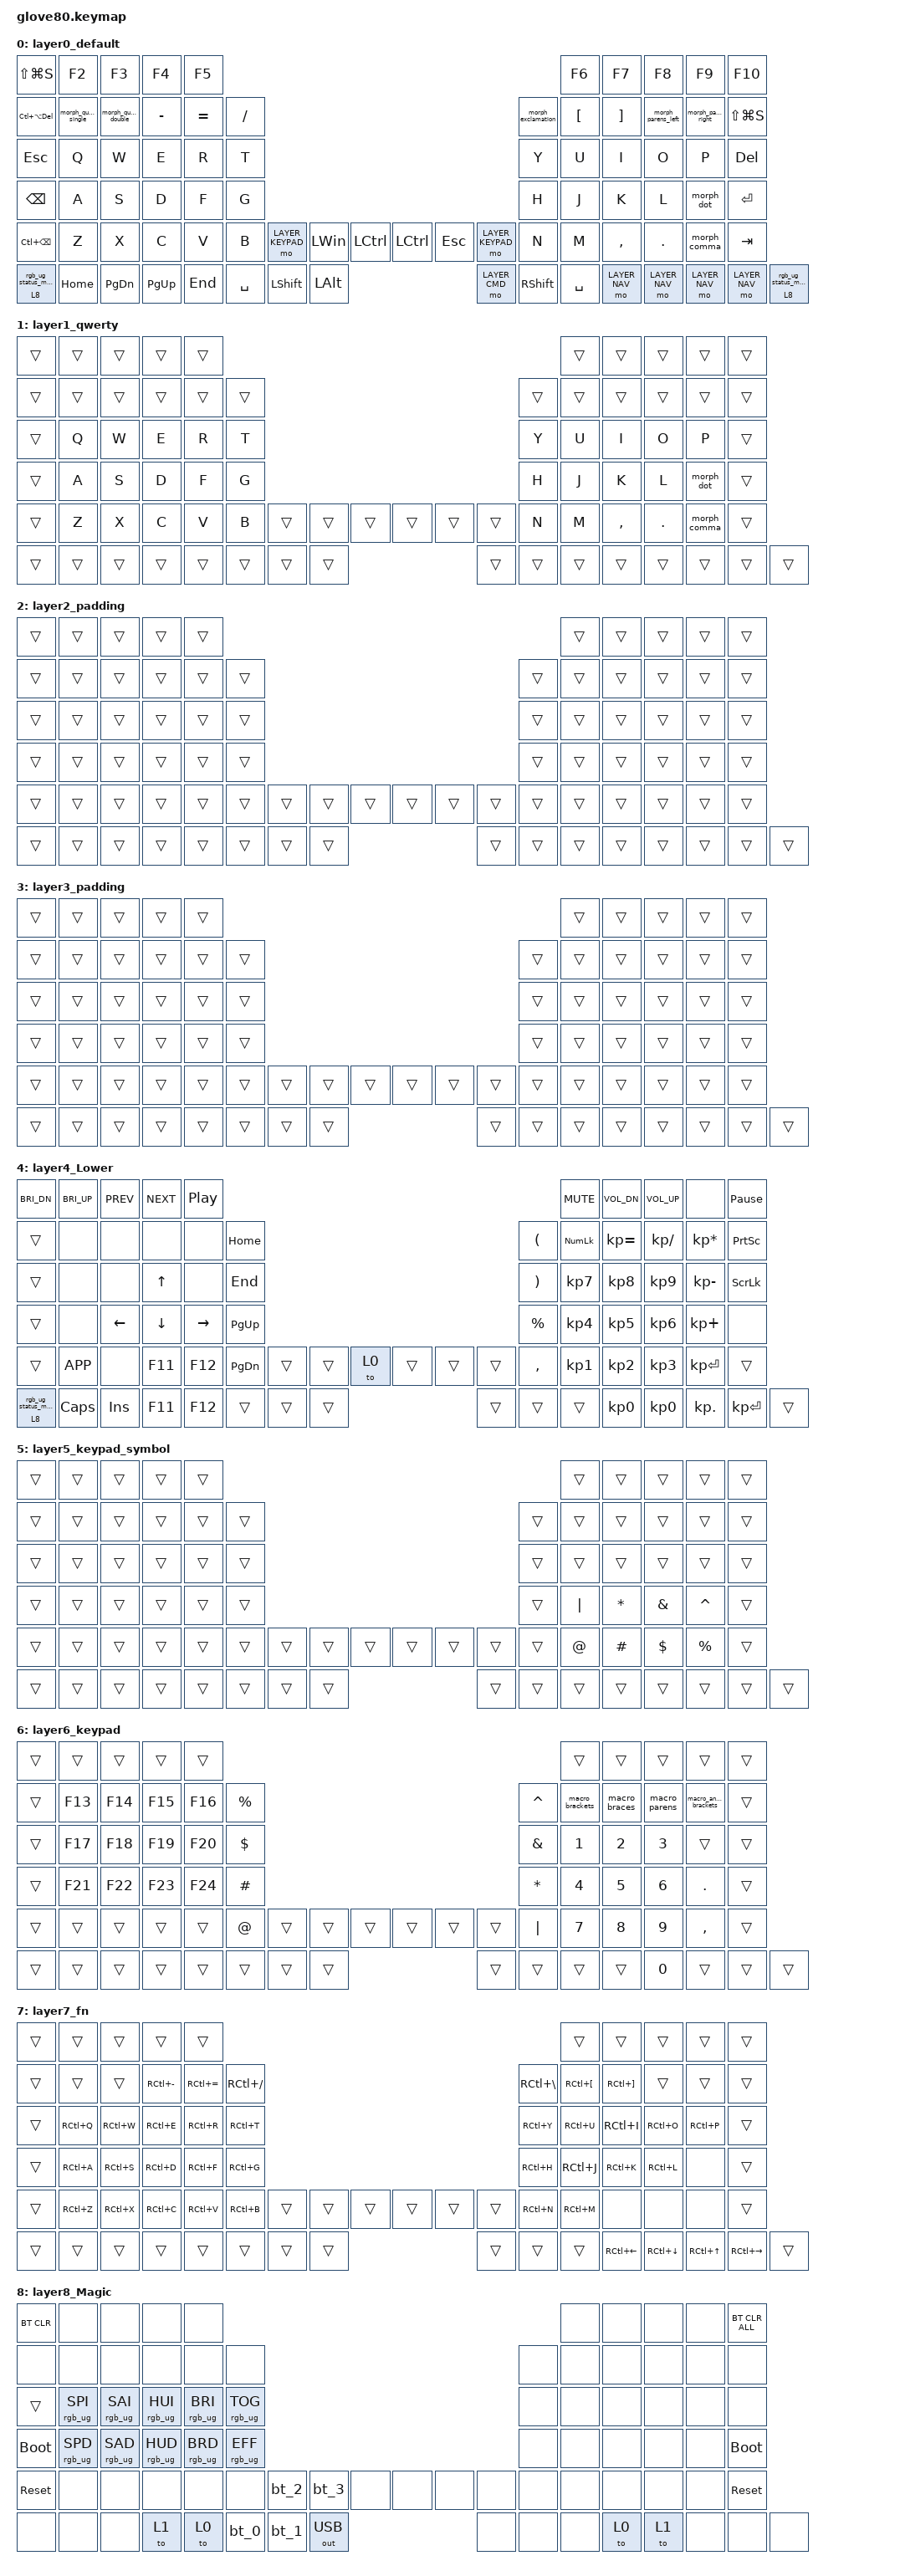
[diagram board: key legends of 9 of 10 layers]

/*
 * Copyright (c) 2020 The ZMK Contributors
 * Copyright (c) 2022 Innaworks Development Limited, trading as MoErgo
 *
 * SPDX-License-Identifier: MIT
 */


/* THIS FILE WAS GENERATED BY GLOVE80 LAYOUT EDITOR
 *
 * This file was generated automatically. You may or may not want to
 * edit it directly.
 */

#include <behaviors.dtsi>
/* Include all behaviour includes needed by system behaviors/macros */
#include <dt-bindings/zmk/outputs.h>

/* Include behaviour includes needed by key binds - automatically generated */
#include <dt-bindings/zmk/keys.h>
#include <dt-bindings/zmk/bt.h>
#include <dt-bindings/zmk/rgb.h>
#include <dt-bindings/zmk/outputs.h>

#define LAYER_KEYPAD 6
#define LAYER_CMD 7
#define LAYER_NAV 9

/ {
    /* Glove80 system behavior & macros */
    behaviors {
        // For the "layer" key, it'd nice to be able to use it as either a shift or a toggle.
        // Configure it as a tap dance, so the first tap (or hold) is a &mo and the second tap is a &to
        lower: tap_dance_0 {
            compatible = "zmk,behavior-tap-dance";
            label = "LAYER_TAP_DANCE";
            #binding-cells = <0>;
            tapping-term-ms = <200>;
            bindings = <&mo 1>, <&to 1>;
        };
    };

    combos {
        compatible = "zmk,combos";
        combo_esc {
            timeout-ms = <50>;
            key-positions = <52 57>; // This needs to change for each board
            bindings = <&kp BSPC>;
        };
    };

    macros {
        rgb_ug_status_macro: rgb_ug_status_macro_0 {
            label = "RGB_UG_STATUS";
            compatible = "zmk,behavior-macro";
            #binding-cells = <0>;
            bindings = <&rgb_ug RGB_STATUS>;
        };

        bt_0: bt_profile_macro_0 {
            label = "BT_0";
            compatible = "zmk,behavior-macro";
            #binding-cells = <0>;
            bindings = <&out OUT_BLE>, <&bt BT_SEL 0>;
        };

        bt_1: bt_profile_macro_1 {
            label = "BT_1";
            compatible = "zmk,behavior-macro";
            #binding-cells = <0>;
            bindings = <&out OUT_BLE>, <&bt BT_SEL 1>;
        };

        bt_2: bt_profile_macro_2 {
            label = "BT_2";
            compatible = "zmk,behavior-macro";
            #binding-cells = <0>;
            bindings = <&out OUT_BLE>, <&bt BT_SEL 2>;
        };

        bt_3: bt_profile_macro_3 {
            label = "BT_3";
            compatible = "zmk,behavior-macro";
            #binding-cells = <0>;
            bindings = <&out OUT_BLE>, <&bt BT_SEL 3>;
        };

        macro_quotes: macro_quotes {
            compatible = "zmk,behavior-macro";
            label = "macro_quotes";
            #binding-cells = <0>;
            bindings = <&kp SQT>, <&kp SQT>, <&kp LEFT>;
        };

        macro_dquotes: macro_dquotes {
            compatible = "zmk,behavior-macro";
            label = "macro_dquotes";
            #binding-cells = <0>;
            bindings = <&kp DQT>, <&kp DQT>, <&kp LEFT>;
        };

        macro_braces: macro_braces {
            compatible = "zmk,behavior-macro";
            label = "macro_braces";
            #binding-cells = <0>;
            bindings = <&kp LBRC>, <&kp RBRC>, <&kp LEFT>;
        };

        macro_parens: macro_parens {
            compatible = "zmk,behavior-macro";
            label = "macro_parens";
            #binding-cells = <0>;
            bindings = <&kp LPAR>, <&kp RPAR>, <&kp LEFT>;
        };

        macro_brackets: macro_brackets {
            compatible = "zmk,behavior-macro";
            label = "macro_brackets";
            #binding-cells = <0>;
            bindings = <&kp LBKT>, <&kp RBKT>, <&kp LEFT>;
        };

        macro_angle_brackets: macro_angle_brackets {
            compatible = "zmk,behavior-macro";
            label = "macro_angle_brackets";
            #binding-cells = <0>;
            bindings = <&kp LT>, <&kp GT>, <&kp LEFT>;
        };
    };

    magic: magic_hold_tap {
        compatible = "zmk,behavior-hold-tap";
        label = "MAGIC_HOLD_TAP";
        #binding-cells = <2>;
        flavor = "tap-preferred";
        tapping-term-ms = <200>;
        bindings = <&mo>, <&rgb_ug_status_macro>;
    };

    /* Custom Defined Behaviors */

   mo_key: behavior_mo_key {
        compatible = "zmk,behavior-hold-tap";
        label = "mo_key";
        #binding-cells = <2>;
        tapping-term-ms = <200>;
        quick_tap_ms = <175>;
        flavor = "tap-preferred";
        bindings = <&mo>, <&kp>;
    };

    hr_mod: homerow_mods {
        compatible = "zmk,behavior-hold-tap";
        label = "HOMEROW_MODS";
        #binding-cells = <2>;
        tapping-term-ms = <130>;
        quick-tap-ms = <0>;
        flavor = "tap-preferred";
        bindings = <&kp>, <&kp>;
    };

    shift_mod: shift_hold_tap {
        compatible = "zmk,behavior-hold-tap";
        label = "shift_mod_HOLD_TAP";
        #binding-cells = <2>;
        flavor = "tap-unless-interrupted";
        tapping-term-ms = <130>;                        // <---[[produces tap if held longer than tapping-term-ms]]
        quick-tap-ms = <200>;
        bindings = <&kp>, <&kp>;
    };


    // &dot_override,
    morph_dot: morph_dot {
        compatible = "zmk,behavior-mod-morph";
        label = "MORPH_DOT";
        #binding-cells = <0>;
        bindings = <&kp PERIOD>, <&kp COLON>;
        mods = <(MOD_LSFT|MOD_RSFT)>;
    };
    // &comma_override,
    morph_comma: morph_comma {
        compatible = "zmk,behavior-mod-morph";
        label = "MORPH_COMMA";
        #binding-cells = <0>;
        bindings = <&kp COMMA>, <&kp SEMICOLON>;
        mods = <(MOD_LSFT|MOD_RSFT)>;
    };
    // &parens_left_override,
    morph_parens_left: morph_parens_left {
        compatible = "zmk,behavior-mod-morph";
        label = "MORPH_PARENS_LEFT";
        #binding-cells = <0>;
        bindings = <&kp LEFT_PARENTHESIS>, <&kp LESS_THAN>;
        mods = <(MOD_LSFT|MOD_RSFT)>;
    };
    // &parens_right_override,
    morph_parens_right: morph_parens_right {
        compatible = "zmk,behavior-mod-morph";
        label = "MORPH_PARENS_RIGHT";
        #binding-cells = <0>;
        bindings = <&kp RIGHT_PARENTHESIS>, <&kp GREATER_THAN>;
        mods = <(MOD_LSFT|MOD_RSFT)>;
    };
    // &exclamation_override,
    morph_exclamation: morph_exclamation {
        compatible = "zmk,behavior-mod-morph";
        label = "MORPH_EXCLAMATION";
        #binding-cells = <0>;
        bindings = <&kp BACKSLASH>, <&kp EXCLAMATION>;
        mods = <(MOD_LSFT|MOD_RSFT)>;
    };
    // &quote_single_override,
    morph_quote_single: morph_quote_single {
        compatible = "zmk,behavior-mod-morph";
        label = "MORPH_QUOTE_SINGLE";
        #binding-cells = <0>;
        bindings = <&kp SINGLE_QUOTE>, <&kp GRAVE>;
        mods = <(MOD_LSFT|MOD_RSFT)>;
    };
    // &quote_double_override,
    morph_quote_double: morph_quote_double {
        compatible = "zmk,behavior-mod-morph";
        label = "MORPH_QUOTE_DOUBLE";
        #binding-cells = <0>;
        bindings = <&kp DOUBLE_QUOTES>, <&kp TILDE>;
        mods = <(MOD_LSFT|MOD_RSFT)>;
    };



    /* Automatically generated keymap */
    keymap {
        compatible = "zmk,keymap";

layer0_default {
// -----------------------------------------------------------------------------------------
// Thumb Cluster Layout (unified across all keyboards):
//
//     Left Thumb Cluster              Right Thumb Cluster
//     (Left hand)                     (Right hand)
//     ┌───┬───┬───┐                   ┌───┬───┬───┐
//     │L6 │L5 │L4 │                   │R4 │R5 │R6 │
//     ├───┼───┼───┤                   ├───┼───┼───┤
//     │L1 │L2 │L3 │                   │R3 │R2 │R1 │
//     └───┴───┴───┘                   └───┴───┴───┘
//    (thumb)  (far)                  (far)  (thumb)
//
// Position Mapping:
//   L1=SPACE  L2=LSHIFT  L3=LALT  L4=LCTRL  L5=LWIN  L6=mo_KEYPAD
//   R1=SPACE  R2=RSHIFT  R3=mo_CMD  R4=LCTRL  R5=ESC  R6=mo_KEYPAD
//
// glove80 Matrix Positions:
//   Row 4 (Z row): ... [L6:KEYPAD] [L5:WIN] [L4:CTRL] [R4:CTRL] [R5:ESC] [R6:KEYPAD] ...
//   Row 5 (bottom): ... [L1:SPC] [L2:LSHFT] [L3:LALT] | [R3:CMD] [R2:RSHFT] [R1:SPC] ...
// -----------------------------------------------------------------------------------------
bindings = <
&kp LS(LG(S))       &kp F2                  &kp F3                  &kp F4          &kp F5                                                                                                                                                                &kp F6     &kp F7    &kp F8                 &kp F9                  &kp F10
&kp LC(LA(DEL))     &morph_quote_single     &morph_quote_double     &kp MINUS       &kp EQUAL   &kp SLASH                                                                                                                      &morph_exclamation         &kp LBKT   &kp RBKT  &morph_parens_left     &morph_parens_right     &kp LS(LG(S))
&kp ESC             &kp Q                   &kp W                   &kp E           &kp R       &kp T                                                                                                                          &kp Y                      &kp U      &kp I     &kp O                  &kp P                   &kp DEL
&kp BSPC            &kp A                   &kp S                   &kp D           &kp F       &kp G                                                                                                                          &kp H                      &kp J      &kp K     &kp L                  &morph_dot              &kp ENTER
&kp LC(BSPC)        &kp Z                   &kp X                   &kp C           &kp V       &kp B                &mo LAYER_KEYPAD  &kp LEFT_WIN    &kp LEFT_CONTROL  &kp LEFT_CONTROL  &kp ESCAPE     &mo LAYER_KEYPAD     &kp N                      &kp M      &kp COMMA &kp DOT                &morph_comma            &kp TAB
&magic 8 0          &kp HOME                &kp PAGE_DOWN           &kp PAGE_UP     &kp END                          &kp SPACE         &kp LEFT_SHIFT  &kp LEFT_ALT      &mo LAYER_CMD  &kp RIGHT_SHIFT   &kp SPACE                                       &mo LAYER_NAV   &mo LAYER_NAV  &mo LAYER_NAV                 &mo LAYER_NAV               &magic 8 0
>;
};
layer1_qwerty {
bindings = <
&trans  &trans  &trans  &trans  &trans                                                              &trans  &trans      &trans      &trans          &trans
&trans  &trans  &trans  &trans  &trans  &trans                                              &trans  &trans  &trans      &trans      &trans          &trans
&trans  &kp Q   &kp W   &kp E   &kp R   &kp T                                               &kp Y   &kp U   &kp I       &kp O       &kp P           &trans
&trans  &kp A   &kp S   &kp D   &kp F   &kp G                                               &kp H   &kp J   &kp K       &kp L       &morph_dot      &trans
&trans  &kp Z   &kp X   &kp C   &kp V   &kp B   &trans &trans &trans &trans &trans &trans   &kp N   &kp M   &kp COMMA   &kp DOT     &morph_comma    &trans
&trans  &trans  &trans  &trans  &trans          &trans &trans &trans &trans &trans &trans           &trans  &trans      &trans      &trans          &trans
>;
};

layer2_padding {
bindings = <
&trans  &trans  &trans  &trans  &trans                                                             &trans  &trans  &trans  &trans  &trans
&trans  &trans  &trans  &trans  &trans  &trans                                             &trans  &trans  &trans  &trans  &trans  &trans
&trans  &trans  &trans  &trans  &trans  &trans                                             &trans  &trans  &trans  &trans  &trans  &trans
&trans  &trans  &trans  &trans  &trans  &trans                                             &trans  &trans  &trans  &trans  &trans  &trans
&trans  &trans  &trans  &trans  &trans  &trans  &trans &trans &trans &trans &trans &trans  &trans  &trans  &trans  &trans  &trans  &trans
&trans  &trans  &trans  &trans  &trans          &trans &trans &trans &trans &trans &trans          &trans  &trans  &trans  &trans  &trans
>;
};

layer3_padding {
bindings = <
&trans  &trans  &trans  &trans  &trans                                                             &trans  &trans  &trans  &trans  &trans
&trans  &trans  &trans  &trans  &trans  &trans                                             &trans  &trans  &trans  &trans  &trans  &trans
&trans  &trans  &trans  &trans  &trans  &trans                                             &trans  &trans  &trans  &trans  &trans  &trans
&trans  &trans  &trans  &trans  &trans  &trans                                             &trans  &trans  &trans  &trans  &trans  &trans
&trans  &trans  &trans  &trans  &trans  &trans  &trans &trans &trans &trans &trans &trans  &trans  &trans  &trans  &trans  &trans  &trans
&trans  &trans  &trans  &trans  &trans          &trans &trans &trans &trans &trans &trans          &trans  &trans  &trans  &trans  &trans
>;
};

layer4_Lower {
            bindings = <
 &kp C_BRI_DN  &kp C_BRI_UP      &kp C_PREV      &kp C_NEXT         &kp C_PP                                                                                    &kp C_MUTE  &kp C_VOL_DN  &kp C_VOL_UP            &none  &kp PAUSE_BREAK
       &trans         &none           &none           &none            &none   &kp HOME                                                   &kp LEFT_PARENTHESIS  &kp KP_NUM  &kp KP_EQUAL  &kp KP_SLASH  &kp KP_MULTIPLY  &kp PRINTSCREEN
       &trans         &none           &none    &kp UP_ARROW            &none    &kp END                                                  &kp RIGHT_PARENTHESIS   &kp KP_N7     &kp KP_N8     &kp KP_N9     &kp KP_MINUS   &kp SCROLLLOCK
       &trans         &none  &kp LEFT_ARROW  &kp DOWN_ARROW  &kp RIGHT_ARROW  &kp PG_UP                                                            &kp PERCENT   &kp KP_N4     &kp KP_N5     &kp KP_N6      &kp KP_PLUS            &none
       &trans     &kp K_APP           &none         &kp F11          &kp F12  &kp PG_DN  &trans  &trans   &to 0  &trans  &trans  &trans              &kp COMMA   &kp KP_N1     &kp KP_N2     &kp KP_N3     &kp KP_ENTER           &trans
   &magic 8 0      &kp CAPS         &kp INS         &kp F11          &kp F12             &trans  &trans  &trans  &trans  &trans  &trans                          &kp KP_N0     &kp KP_N0    &kp KP_DOT     &kp KP_ENTER           &trans
            >;
        };

layer5_keypad_symbol {
bindings = <
&trans  &trans  &trans  &trans  &trans                                                             &trans  &trans  &trans  &trans  &trans
&trans  &trans  &trans  &trans  &trans  &trans                                             &trans  &trans  &trans  &trans  &trans  &trans
&trans  &trans  &trans  &trans  &trans  &trans                                             &trans  &trans  &trans  &trans  &trans  &trans
&trans  &trans  &trans  &trans  &trans  &trans                                             &trans  &kp PIPE     &kp STAR      &kp AMPERSAND &kp CARET  &trans
&trans  &trans  &trans  &trans  &trans  &trans  &trans &trans &trans &trans &trans &trans  &trans  &kp AT_SIGN  &kp POUND     &kp DOLLAR    &kp PERCENT  &trans
&trans  &trans  &trans  &trans  &trans          &trans &trans &trans &trans &trans &trans          &trans  &trans  &trans  &trans  &trans
>;
};


layer6_keypad {
bindings = <
&trans          &trans          &trans          &trans          &trans                                                                                         &trans              &trans          &trans          &trans                  &trans
&trans          &kp F13         &kp F14         &kp F15         &kp F16         &kp PERCENT                                                    &kp CARET       &macro_brackets     &macro_braces   &macro_parens   &macro_angle_brackets   &trans
&trans          &kp F17         &kp F18         &kp F19         &kp F20         &kp DOLLAR                                                     &kp AMPERSAND   &kp N1              &kp N2          &kp N3          &trans                  &trans
&trans          &kp F21         &kp F22         &kp F23         &kp F24         &kp POUND                                                      &kp STAR        &kp N4              &kp N5          &kp N6          &kp DOT                 &trans
&trans          &trans          &trans          &trans          &trans          &kp AT_SIGN         &trans &trans &trans &trans &trans &trans  &kp PIPE        &kp N7              &kp N8          &kp N9          &kp COMMA               &trans
&trans          &trans          &trans          &trans          &trans                              &trans &trans &trans &trans &trans &trans                  &trans              &kp N0          &trans          &trans                  &trans
>;
};

layer7_fn {
bindings = <
&trans  &trans      &trans      &trans          &trans                                                                                              &trans               &trans                 &trans    &trans    &trans
&trans  &trans      &trans      &kp RC(MINUS)   &kp RC(EQUAL)   &kp RC(SLASH)                                                   &kp RC(BACKSLASH)   &kp RC(LEFT_BRACKET) &kp RC(RIGHT_BRACKET)  &trans    &trans    &trans
&trans  &kp RC(Q)   &kp RC(W)   &kp RC(E)       &kp RC(R)       &kp RC(T)                                                       &kp RC(Y)           &kp RC(U)            &kp RC(I)              &kp RC(O) &kp RC(P) &trans
&trans  &kp RC(A)   &kp RC(S)   &kp RC(D)       &kp RC(F)       &kp RC(G)                                                       &kp RC(H)           &kp RC(J)            &kp RC(K)              &kp RC(L) &none     &trans
&trans  &kp RC(Z)   &kp RC(X)   &kp RC(C)       &kp RC(V)       &kp RC(B)       &trans &trans &trans &trans &trans &trans       &kp RC(N)           &kp RC(M)            &none                  &none     &none     &trans
&trans  &trans      &trans      &trans          &trans                          &trans &trans &trans &trans &trans &trans                           &kp RC(LEFT)         &kp RC(DOWN)           &kp RC(UP) &kp RC(RIGHT) &trans
>;
};




        layer8_Magic {
            bindings = <
  &bt BT_CLR            &none            &none            &none            &none                                                                                  &none   &none   &none   &none  &bt BT_CLR_ALL
       &none            &none            &none            &none            &none            &none                                                         &none   &none   &none   &none   &none           &none
      &trans  &rgb_ug RGB_SPI  &rgb_ug RGB_SAI  &rgb_ug RGB_HUI  &rgb_ug RGB_BRI  &rgb_ug RGB_TOG                                                         &none   &none   &none   &none   &none           &none
 &bootloader  &rgb_ug RGB_SPD  &rgb_ug RGB_SAD  &rgb_ug RGB_HUD  &rgb_ug RGB_BRD  &rgb_ug RGB_EFF                                                         &none   &none   &none   &none   &none     &bootloader
  &sys_reset            &none            &none            &none            &none            &none   &bt_2   &bt_3         &none   &none   &none   &none   &none   &none   &none   &none   &none      &sys_reset
       &none            &none            &none            &to 1            &to 0                    &bt_0   &bt_1  &out OUT_USB   &none   &none   &none           &to 0   &to 1   &none   &none           &none
            >;
        };

        layer9_navigation {
            // -----------------------------------------------------------------------------------------
            // Navigation Layer for Modeless Editing
            // 
            // Design: Right hand focuses on navigation motions (IJKL as inverted-T arrows)
            //         Left hand provides editing commands (cut/copy/paste, undo/redo)
            //         Hold SHIFT in this layer to convert navigation to selection
            //
            // Right Hand Navigation Layout:
            //   Row 1: GoBack | Word← |   ↑   | Word→ | GoForward
            //   Row 2: Home   |   ←   |   ↓   |   →   | End
            //   Row 3: DelW←  | Bksp  | PgDn  | PgUp  | Del | DelW→
            //
            // Left Hand Editing Layout:
            //   Row 1: Redo     | Undo    | DelLine | DupLine | (unused)
            //   Row 2: SelAll   | Cut     | Copy    | Paste   | SelLine
            //   Row 3: MvLn↑    | MvLn↓   | GoDef   | FindRef | CmdPalette
            // -----------------------------------------------------------------------------------------
            bindings = <
&trans          &trans          &trans          &trans          &trans                                                                                         &trans              &trans                &trans           &trans                &trans
&trans          &trans          &trans          &trans          &trans          &trans                                                     &trans              &trans                &trans           &trans                &trans              &trans
&trans          &kp LG(LS(Z))   &kp LG(Z)       &kp LG(LS(K))   &kp LG(LS(D))   &trans                                                     &kp LC(LS(MINUS))   &kp LA(LEFT)          &kp UP           &kp LA(RIGHT)         &kp LC(MINUS)       &trans
&trans          &kp LG(A)       &kp LG(X)       &kp LG(C)       &kp LG(V)       &kp LG(L)                                                  &kp LG(LEFT)        &kp LEFT              &kp DOWN         &kp RIGHT             &kp LG(RIGHT)       &trans
&trans          &kp LA(UP)      &kp LA(DOWN)    &kp F12         &kp LS(F12)     &kp LG(LS(P))   &trans &trans &trans &trans &trans &trans  &kp LA(BSPC)        &kp BSPC              &kp PG_DN        &kp PG_UP             &kp DEL             &kp LA(DEL)   &trans
&trans          &trans          &trans          &trans          &trans                          &trans &trans &trans &trans &trans &trans                      &trans                &trans           &trans                &trans              &trans
            >;
        };

    };
};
